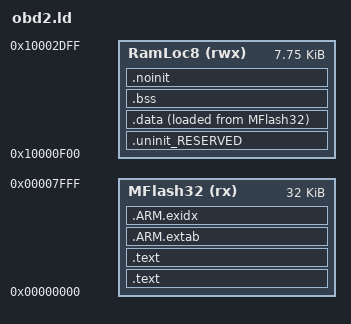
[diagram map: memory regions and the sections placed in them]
/*
 * GENERATED FILE - DO NOT EDIT
 * (c) Code Red Technologies Ltd, 2008-2014
 * (c) NXP Semiconductors 2013-2014
 * Linker script memory definitions
 * Created from LinkMemoryTemplate
 * By LPCXpresso v7.1.1 [Build 125] [2014-04-01]  on Mon Apr 28 21:04:43 CST 2014)
*/

 GROUP(
 libcr_semihost.a
 libcr_c.a
 libcr_eabihelpers.a
 )

MEMORY
{
  /* Define each memory region */
  MFlash32 (rx) : ORIGIN = 0x0, LENGTH = 0x8000 /* 32K bytes */
  RamLoc8 (rwx) : ORIGIN = 0x10000F00, LENGTH = 0x1F00 /* 8K bytes */


}
  /* Define a symbol for the top of each memory region */
  __top_MFlash32 = 0x0 + 0x8000;
  __top_RamLoc8 = 0x10000F00 + 0x1F00;



ENTRY(ResetISR)

SECTIONS
{

    /* MAIN TEXT SECTION */    
    .text : ALIGN(4)
    {
        FILL(0xff)
        __vectors_start__ = ABSOLUTE(.) ;
        KEEP(*(.isr_vector))
        
        /* Global Section Table */
        . = ALIGN(4) ;
        __section_table_start = .;
        __data_section_table = .;
        LONG(LOADADDR(.data));
        LONG(    ADDR(.data));
        LONG(  SIZEOF(.data));
        __data_section_table_end = .;
        __bss_section_table = .;
        LONG(    ADDR(.bss));
        LONG(  SIZEOF(.bss));
        __bss_section_table_end = .;
        __section_table_end = . ;
        /* End of Global Section Table */
        

        *(.after_vectors*)
        
    } >MFlash32
    
    .text : ALIGN(4)    
    {
         *(.text*)
        *(.rodata .rodata.* .constdata .constdata.*)
        . = ALIGN(4);
        
    } > MFlash32

    /*
     * for exception handling/unwind - some Newlib functions (in common
     * with C++ and STDC++) use this. 
     */
    .ARM.extab : ALIGN(4)
    {
    	*(.ARM.extab* .gnu.linkonce.armextab.*)
    } > MFlash32
    __exidx_start = .;
    
    .ARM.exidx : ALIGN(4)
    {
    	*(.ARM.exidx* .gnu.linkonce.armexidx.*)
    } > MFlash32
    __exidx_end = .;
    
    _etext = .;
        
    
    /* MAIN DATA SECTION */
    

    .uninit_RESERVED : ALIGN(4)
    {
        KEEP(*(.bss.$RESERVED*))
        . = ALIGN(4) ;
        _end_uninit_RESERVED = .;
    } > RamLoc8

	
	/* Main DATA section (RamLoc8) */
	.data : ALIGN(4)
	{
	   FILL(0xff)
	   _data = . ;
	   *(vtable)
	   *(.ramfunc*)
	   *(.data*)
	   . = ALIGN(4) ;
	   _edata = . ;
	} > RamLoc8 AT>MFlash32


    /* MAIN BSS SECTION */
    .bss : ALIGN(4)
    {
        _bss = .;
        *(.bss*)
        *(COMMON)
        . = ALIGN(4) ;
        _ebss = .;
        PROVIDE(end = .);
    } > RamLoc8
        
    
    /* DEFAULT NOINIT SECTION */
    .noinit (NOLOAD): ALIGN(4)
    {
        _noinit = .;
        *(.noinit*) 
         . = ALIGN(4) ;
        _end_noinit = .;
    } > RamLoc8
    
    PROVIDE(_pvHeapStart = .);
    PROVIDE(_vStackTop = __top_RamLoc8 - 0);
}

